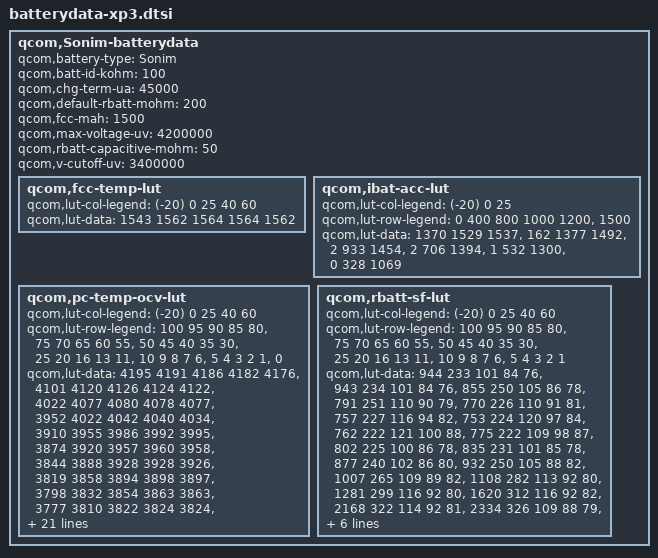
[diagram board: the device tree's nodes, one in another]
/* Copyright (c) 2014-2019, The Linux Foundation. All rights reserved.
 *
 * This program is free software; you can redistribute it and/or modify
 * it under the terms of the GNU General Public License version 2 and
 * only version 2 as published by the Free Software Foundation.
 *
 * This program is distributed in the hope that it will be useful,
 * but WITHOUT ANY WARRANTY; without even the implied warranty of
 * MERCHANTABILITY or FITNESS FOR A PARTICULAR PURPOSE.  See the
 * GNU General Public License for more details.
 */

qcom,Sonim-batterydata {
	qcom,battery-type = "Sonim";
	qcom,batt-id-kohm = <100>;
	qcom,chg-term-ua = <45000>;
	qcom,default-rbatt-mohm = <200>;
	qcom,fcc-mah = <1500>;
	qcom,max-voltage-uv = <4200000>;
	qcom,rbatt-capacitive-mohm = <50>;
	qcom,v-cutoff-uv = <3400000>;

	qcom,fcc-temp-lut {
		qcom,lut-col-legend = <(-20) 0 25 40 60>;
		qcom,lut-data = <1543 1562 1564 1564 1562>;
	};

	qcom,ibat-acc-lut {
		qcom,lut-col-legend = <(-20) 0 25>;
		qcom,lut-row-legend = <0 400 800 1000 1200>,
					<1500>;
		qcom,lut-data = <1370 1529 1537>,
				<162 1377 1492>,
				<2 933 1454>,
				<2 706 1394>,
				<1 532 1300>,
				<0 328 1069>;
	};

	qcom,pc-temp-ocv-lut {
		qcom,lut-col-legend = <(-20) 0 25 40 60>;
		qcom,lut-row-legend = <100 95 90 85 80>,
					<75 70 65 60 55>,
					<50 45 40 35 30>,
					<25 20 16 13 11>,
					<10 9 8 7 6>,
					<5 4 3 2 1>,
					<0>;
		qcom,lut-data = <4195 4191 4186 4182 4176>,
				<4101 4120 4126 4124 4122>,
				<4022 4077 4080 4078 4077>,
				<3952 4022 4042 4040 4034>,
				<3910 3955 3986 3992 3995>,
				<3874 3920 3957 3960 3958>,
				<3844 3888 3928 3928 3926>,
				<3819 3858 3894 3898 3897>,
				<3798 3832 3854 3863 3863>,
				<3777 3810 3822 3824 3824>,
				<3756 3793 3802 3803 3803>,
				<3736 3780 3786 3787 3787>,
				<3716 3770 3775 3774 3774>,
				<3695 3762 3768 3764 3762>,
				<3672 3752 3762 3757 3748>,
				<3642 3738 3752 3746 3732>,
				<3599 3713 3735 3727 3714>,
				<3538 3686 3704 3698 3684>,
				<3459 3672 3684 3678 3666>,
				<3388 3662 3680 3676 3665>,
				<3351 3656 3678 3674 3664>,
				<3313 3651 3676 3673 3662>,
				<3282 3644 3673 3670 3660>,
				<3246 3634 3668 3667 3656>,
				<3210 3620 3660 3658 3646>,
				<3184 3596 3638 3634 3612>,
				<3162 3550 3589 3584 3562>,
				<3142 3480 3522 3518 3493>,
				<3120 3386 3432 3426 3400>,
				<3086 3250 3290 3286 3255>,
				<3000 3000 3000 3000 3000>;
	};

	qcom,rbatt-sf-lut {
		qcom,lut-col-legend = <(-20) 0 25 40 60>;
		qcom,lut-row-legend = <100 95 90 85 80>,
					<75 70 65 60 55>,
					<50 45 40 35 30>,
					<25 20 16 13 11>,
					<10 9 8 7 6>,
					<5 4 3 2 1>;
		qcom,lut-data = <944 233 101 84 76>,
				<943 234 101 84 76>,
				<855 250 105 86 78>,
				<791 251 110 90 79>,
				<770 226 110 91 81>,
				<757 227 116 94 82>,
				<753 224 120 97 84>,
				<762 222 121 100 88>,
				<775 222 109 98 87>,
				<802 225 100 86 78>,
				<835 231 101 85 78>,
				<877 240 102 86 80>,
				<932 250 105 88 82>,
				<1007 265 109 89 82>,
				<1108 282 113 92 80>,
				<1281 299 116 92 80>,
				<1620 312 116 92 82>,
				<2168 322 114 92 81>,
				<2334 326 109 88 79>,
				<4060 344 114 92 82>,
				<8119 357 118 94 84>,
				<13549 370 122 96 84>,
				<19203 385 127 98 86>,
				<24414 401 133 101 86>,
				<30930 418 137 102 85>,
				<39232 430 138 99 84>,
				<48091 434 140 101 85>,
				<58346 443 152 108 89>,
				<71168 465 168 119 97>,
				<86750 566 212 166 127>;
	};
};
/* TEST_DB_ID=TEST_ID_NOT_SET */
